# boot register map
Vendor: Texas Instruments
Peripheral module from a debugger description file (folder Keystone2).
Registers are 32-bit, read-write, no defined reset value unless marked. A register's access mark holds for its fields unless they carry their own. Offsets are as the file gives them; lines under a group give offsets from that group; [hi:lo] are bit positions; {n}, {i} and the like mark numbered series; 'fields as' and 'values as' point back to an identical list; <NAME> marks a mode.

## BOOT
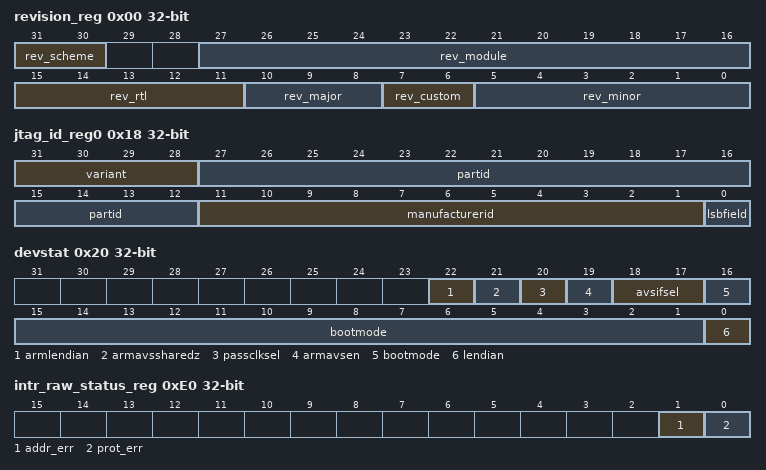
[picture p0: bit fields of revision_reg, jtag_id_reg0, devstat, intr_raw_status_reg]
0x00 revision_reg
  [31:30] rev_scheme, [27:16] rev_module, [15:11] rev_rtl, [10:8] rev_major, [7:6] rev_custom, [5:0] rev_minor
{0x8+4i} die_id_reg{i} (i=0..3)
  [31:0] die_id{i}
0x18 jtag_id_reg0
  [31:28] variant, [27:12] partid, [11:1] manufacturerid, [0] lsbfield
0x20 devstat
  [22] armlendian, [21] armavssharedz, [20] passclksel, [19] armavsen, [18:17] avsifsel, [16:1] bootmode, [0] lendian
0x38 kick_reg0
  [31:0] kick0
0x3C kick_reg1
  [31:0] kick1
0x40 bootaddr_gem_reg access not given — (1 of 8, stride 4)
0xE0 intr_raw_status_reg
  [1] addr_err, [0] prot_err
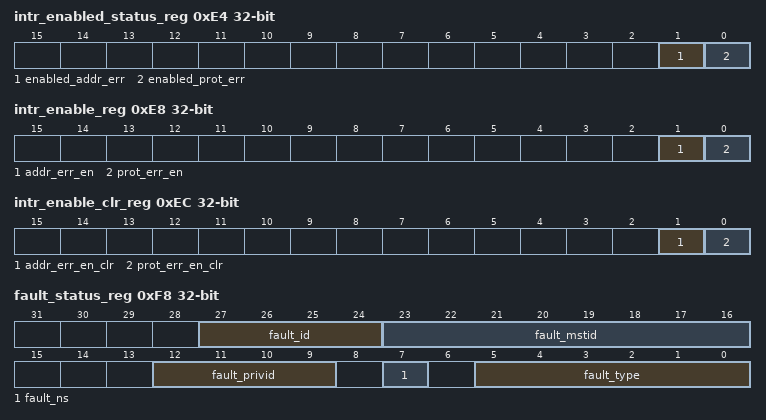
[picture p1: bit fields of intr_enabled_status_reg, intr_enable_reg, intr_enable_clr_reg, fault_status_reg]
0xE4 intr_enabled_status_reg
  [1] enabled_addr_err, [0] enabled_prot_err
0xE8 intr_enable_reg
  [1] addr_err_en, [0] prot_err_en
0xEC intr_enable_clr_reg
  [1] addr_err_en_clr, [0] prot_err_en_clr
0xF0 eoi_reg
  [7:0] eoi_vector
0xF4 fault_address_reg
  [31:0] fault_addr
0xF8 fault_status_reg
  [27:24] fault_id, [23:16] fault_mstid, [12:9] fault_privid, [7] fault_ns, [5:0] fault_type
0xFC fault_clear_reg
  [0] fault_clear
0x110 mac_id0
0x114 mac_id1
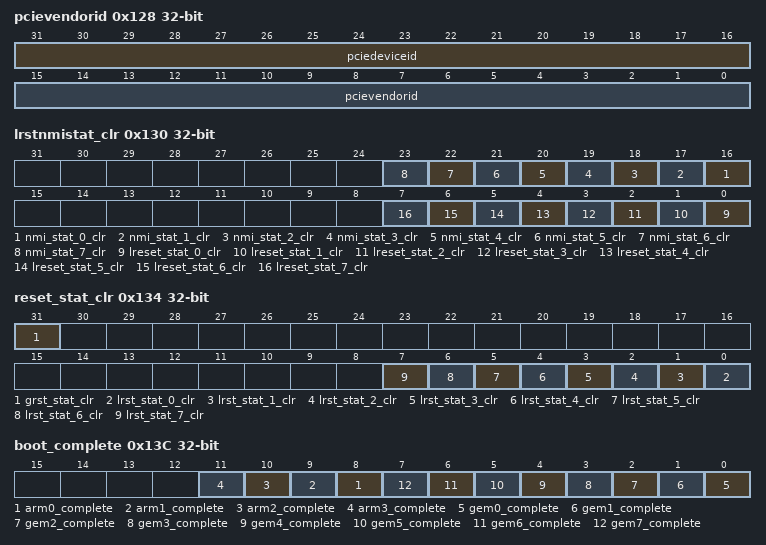
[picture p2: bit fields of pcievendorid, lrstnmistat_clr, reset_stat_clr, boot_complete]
0x128 pcievendorid
  [31:16] pciedeviceid, [15:0] pcievendorid
0x130 lrstnmistat_clr
  [n+16] nmi_stat_{n}_clr (n=0..7), [n] lreset_stat_{n}_clr (n=0..7)
0x134 reset_stat_clr
  [31] grst_stat_clr, [n] lrst_stat_{n}_clr (n=0..7)
0x13C boot_complete
  [n+8] arm{n}_complete (n=0..3), [n] gem{n}_complete (n=0..7)
0x140 boot_progress
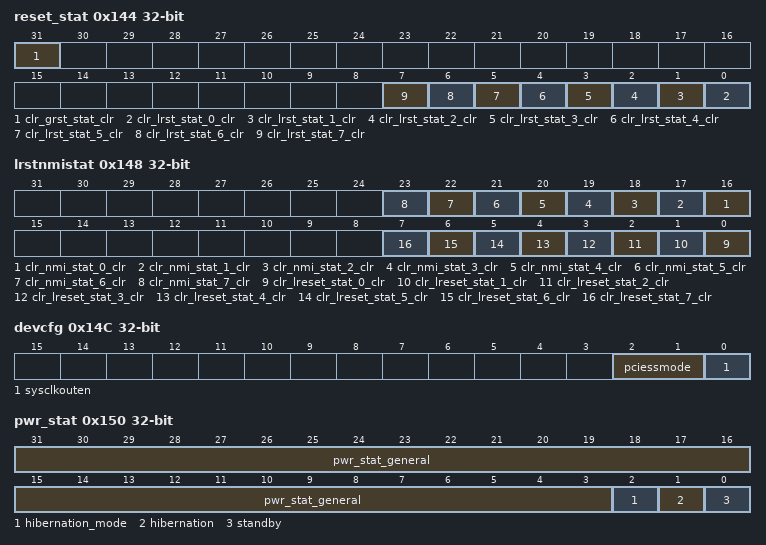
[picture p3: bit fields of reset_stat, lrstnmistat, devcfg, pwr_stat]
0x144 reset_stat
  [31] clr_grst_stat_clr, [n] clr_lrst_stat_{n}_clr (n=0..7)
0x148 lrstnmistat
  [n+16] clr_nmi_stat_{n}_clr (n=0..7), [n] clr_lreset_stat_{n}_clr (n=0..7)
0x14C devcfg
  [2:1] pciessmode, [0] sysclkouten
0x150 pwr_stat
  [31:3] pwr_stat_general, [2] hibernation_mode, [1] hibernation, [0] standby
0x180 class0_efuse_reg
{0x190+4i} sen{i}_0_efuse_reg{i} (i=0..3)
{0x190+4i} sen{i-4}_1_efuse_reg{i} (i=4..7)
{0x190+4i} sen{i-8}_2_efuse_reg{i} (i=8..11)
{0x190+4i} sen{i-12}_3_efuse_reg{i} (i=12..15)
0x200 nmigr — (1 of 8, stride 4)
  [0] nmigr_0_reg_0
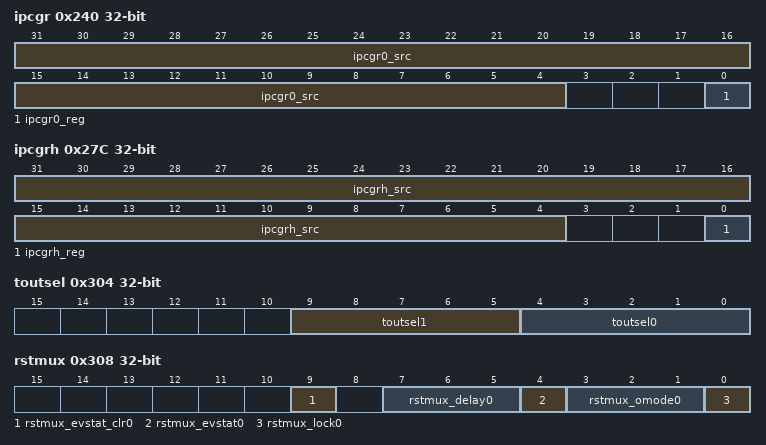
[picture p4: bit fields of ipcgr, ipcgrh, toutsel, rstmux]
0x240 ipcgr — (1 of 12, stride 4)
  [31:4] ipcgr0_src, [0] ipcgr0_reg
0x27C ipcgrh
  [31:4] ipcgrh_src, [0] ipcgrh_reg
0x280 ipcar — (1 of 12, stride 4)
  [31:4] ipcar0_src_clr
0x2BC ipcarh
  [31:4] ipcarh_src_clr
0x300 tinpsel
0x304 toutsel
  [9:5] toutsel1, [4:0] toutsel0
0x308 rstmux — (1 of 12, stride 4)
  [9] rstmux_evstat_clr0, [7:5] rstmux_delay0, [4] rstmux_evstat0, [3:1] rstmux_omode0, [0] rstmux_lock0
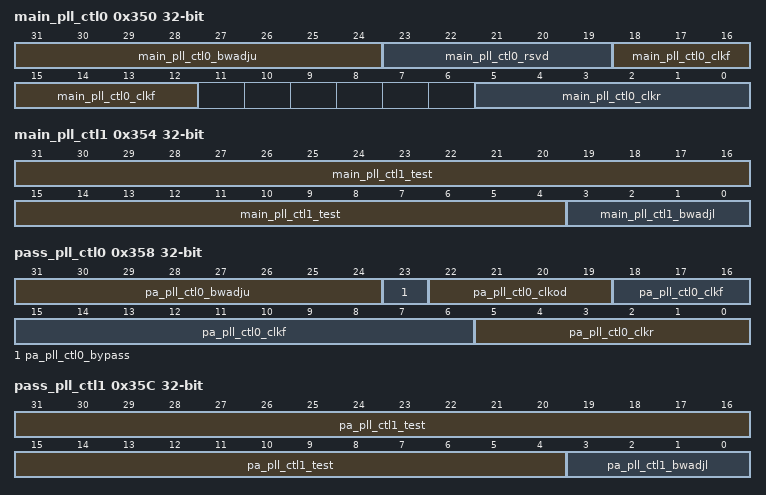
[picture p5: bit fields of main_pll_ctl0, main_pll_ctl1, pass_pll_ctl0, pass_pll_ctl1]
0x350 main_pll_ctl0
  [31:24] main_pll_ctl0_bwadju, [23:19] main_pll_ctl0_rsvd, [18:12] main_pll_ctl0_clkf, [5:0] main_pll_ctl0_clkr
0x354 main_pll_ctl1
  [31:4] main_pll_ctl1_test, [3:0] main_pll_ctl1_bwadjl
0x358 pass_pll_ctl0
  [31:24] pa_pll_ctl0_bwadju, [23] pa_pll_ctl0_bypass, [22:19] pa_pll_ctl0_clkod, [18:6] pa_pll_ctl0_clkf, [5:0] pa_pll_ctl0_clkr
0x35C pass_pll_ctl1
  [31:4] pa_pll_ctl1_test, [3:0] pa_pll_ctl1_bwadjl
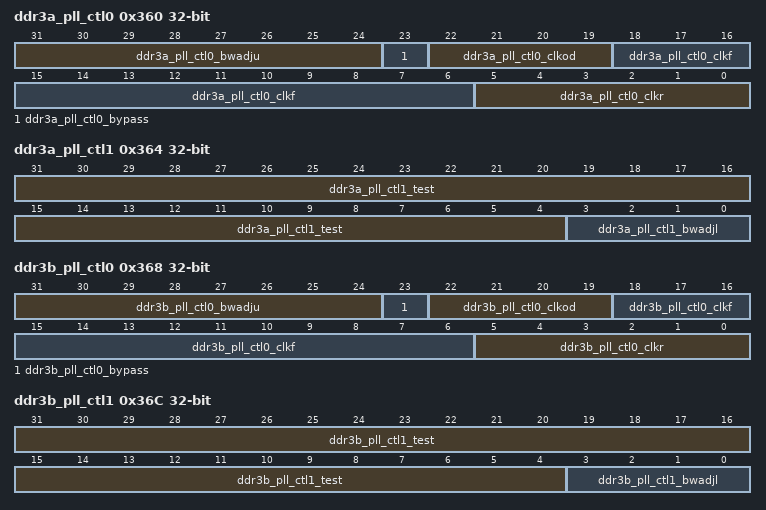
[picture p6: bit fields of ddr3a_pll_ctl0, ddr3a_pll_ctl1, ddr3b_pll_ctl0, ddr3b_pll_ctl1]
0x360 ddr3a_pll_ctl0
  [31:24] ddr3a_pll_ctl0_bwadju, [23] ddr3a_pll_ctl0_bypass, [22:19] ddr3a_pll_ctl0_clkod, [18:6] ddr3a_pll_ctl0_clkf, [5:0] ddr3a_pll_ctl0_clkr
0x364 ddr3a_pll_ctl1
  [31:4] ddr3a_pll_ctl1_test, [3:0] ddr3a_pll_ctl1_bwadjl
0x368 ddr3b_pll_ctl0
  [31:24] ddr3b_pll_ctl0_bwadju, [23] ddr3b_pll_ctl0_bypass, [22:19] ddr3b_pll_ctl0_clkod, [18:6] ddr3b_pll_ctl0_clkf, [5:0] ddr3b_pll_ctl0_clkr
0x36C ddr3b_pll_ctl1
  [31:4] ddr3b_pll_ctl1_test, [3:0] ddr3b_pll_ctl1_bwadjl
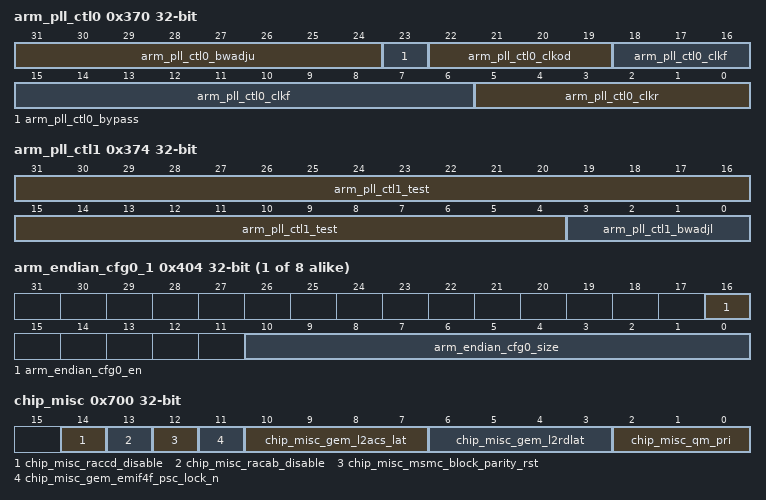
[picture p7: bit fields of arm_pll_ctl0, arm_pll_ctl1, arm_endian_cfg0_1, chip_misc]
0x370 arm_pll_ctl0
  [31:24] arm_pll_ctl0_bwadju, [23] arm_pll_ctl0_bypass, [22:19] arm_pll_ctl0_clkod, [18:6] arm_pll_ctl0_clkf, [5:0] arm_pll_ctl0_clkr
0x374 arm_pll_ctl1
  [31:4] arm_pll_ctl1_test, [3:0] arm_pll_ctl1_bwadjl
{0x400+8i} arm_endian_cfg{i}_0 (i=0..7)
  [23:0] arm_endian_cfg{i}_baddr
{0x404+8i} arm_endian_cfg{i}_1 (i=0..7)
  [16] arm_endian_cfg{i}_en, [10:0] arm_endian_cfg{i}_size
0x700 chip_misc
  [14] chip_misc_raccd_disable, [13] chip_misc_racab_disable, [12] chip_misc_msmc_block_parity_rst, [11] chip_misc_gem_emif4f_psc_lock_n, [10:7] chip_misc_gem_l2acs_lat, [6:3] chip_misc_gem_l2rdlat, [2:0] chip_misc_qm_pri
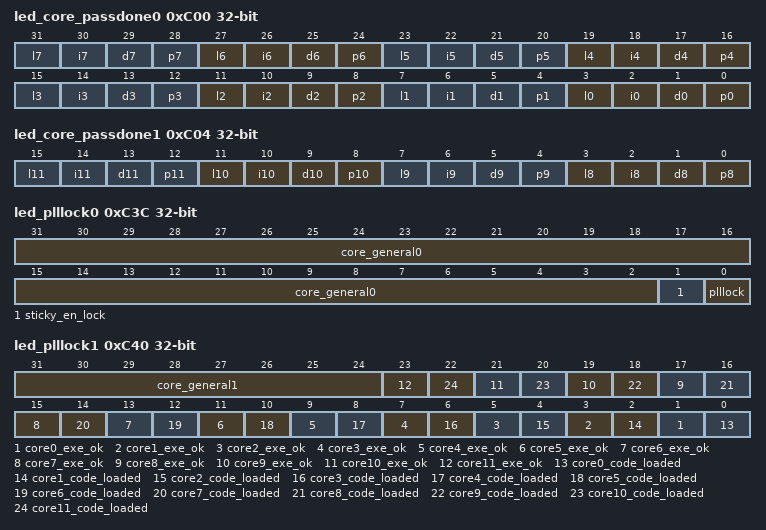
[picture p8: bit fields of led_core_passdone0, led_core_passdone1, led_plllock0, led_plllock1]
0xC00 led_core_passdone0
  [4n+3] l{n} (n=0..7), [4n+2] i{n} (n=0..7), [4n+1] d{n} (n=0..7), [4n] p{n} (n=0..7)
0xC04 led_core_passdone1
  [4n-29] l{n} (n=8..11), [4n-30] i{n} (n=8..11), [4n-31] d{n} (n=8..11), [4n-32] p{n} (n=8..11)
0xC20 led_arm_bootaddr
  [23:0] led_arm_bootaddr
0xC3C led_plllock0
  [31:2] core_general0, [1] sticky_en_lock, [0] plllock
0xC40 led_plllock1
  [31:24] core_general1, [2n+1] core{n}_exe_ok (n=0..11), [2n] core{n}_code_loaded (n=0..11)
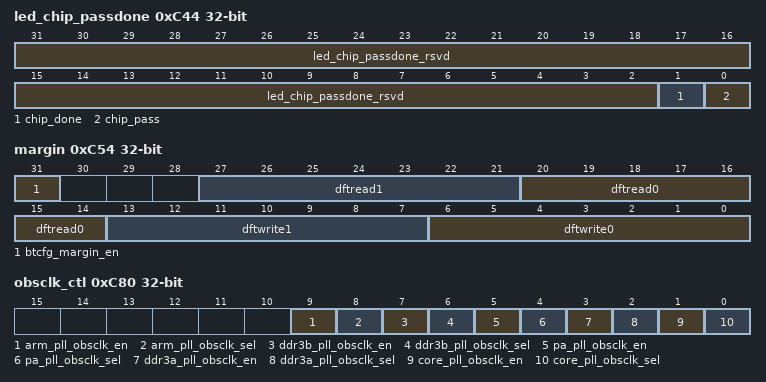
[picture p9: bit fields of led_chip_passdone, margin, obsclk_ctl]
0xC44 led_chip_passdone
  [31:2] led_chip_passdone_rsvd, [1] chip_done, [0] chip_pass
0xC48 led_gpio_clr
  [31:0] led_gpio_src_clr
0xC4C led_gpio
  [31:0] clr_led_gpio_src_clr
0xC50 tdiode
0xC54 margin
  [31] btcfg_margin_en, [27:21] dftread1, [20:14] dftread0, [13:7] dftwrite1, [6:0] dftwrite0
0xC60 efuse_secrom_chksum0
0xC64 efuse_secrom_chksum1
0xC80 obsclk_ctl
  [9] arm_pll_obsclk_en, [8] arm_pll_obsclk_sel, [7] ddr3b_pll_obsclk_en, [6] ddr3b_pll_obsclk_sel, [5] pa_pll_obsclk_en, [4] pa_pll_obsclk_sel, [3] ddr3a_pll_obsclk_en, [2] ddr3a_pll_obsclk_sel, [1] core_pll_obsclk_en, [0] core_pll_obsclk_sel
{0xC90+4i} efuse_rsvd{i} (i=0..3)
